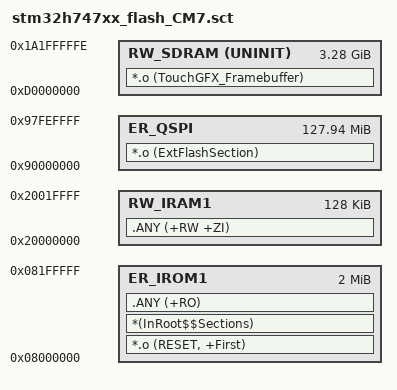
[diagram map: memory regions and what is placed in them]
; *************************************************************
; *** Scatter-Loading Description File generated by uVision ***
; *************************************************************

LR_IROM1 0x08000000 0x00200000  {    ; load region size_region
  ER_IROM1 0x08000000 0x00200000  {  ; load address = execution address
   *.o (RESET, +First)
   *(InRoot$$Sections)
   .ANY (+RO)
  }
  RW_IRAM1 0x20000000 0x00020000{  ; RW data
   .ANY (+RW +ZI)
  }
  RW_SDRAM 0xd0000000 UNINIT 0xd1ffffff {
   *.o (TouchGFX_Framebuffer)
  }
}

LR_QSPI 0x90000000 0x07FF0000  {    ; load region size_region
  ER_QSPI 0x90000000 0x07FF0000  {  ; load address = execution address
   *.o (ExtFlashSection)
  }
}
